# EOS-S3 register map
File version: 0.1
CPU: CM4 r0p1, selectable endian, MPU, FPU, 3 interrupt priority bits
Registers are 32-bit, read-write, reset 0x0 unless marked. A register's access mark holds for its fields unless they carry their own. Offsets are from the block's base; [hi:lo] are bit positions; {n}, {i} and the like mark numbered series.

## MISC — MISC registers
Base 0x40005000
0x00 DBG_MON ro — Debug Monitor information
  [7:0] DEBUG_MON — Reads the debug status/information
0x04 SUBSYS_DBG_MON_SEL — Register for selecting the subsystem routed to the debug monitor
  [2:0] SUBSYS_DEBUG_MON_SEL — Select which subsystem the debug monitors are routed from
    0=Monitor A0 subsystem; 1=monitor_cpu (Monitor the CPU subsystem); 3=monitor_ffe (Monitor the FPGA Fabric subsystem); 4=monitor_audio (Monitor the audio subsystem)
0x08 A0_DBG_MON_SEL — Select A0 debug monitors
  [2:0] A0_DEBUG_MON_SEL — Select debug monitors
    0=use_pmu_monitor (Selects the PMU monitor as the monitor for the A0 subsystem); 1=use_cru_monitor (Selects the CRU monitor as the monitor for the A0 subsystem)
0x0C A0_PMU_DBG_MON_SEL — Selects the data present in the PMU debug monitor. The output will be (Except 0 and 10), {Status0, Status1, ISO, RET, GateCLK_N, Mem_DS, MP_Gate, RP_Gate)
  [5:0] A0_PMU_DEBUG_MON_SEL — Select data to be shown in the PMU debug monitor
    0=show_m4stm_kickoff_and_busy_plus_0x000000 ({M4STM_KickOff, M4STM_BUSY, 6'h0}); 1=show_a1; 2=show_m4; 3=show_m4s0; 4=show_ad5; 5=show_ad4; 6=show_ad3; 7=show_ad2; 8=show_ad1; 9=show_ad0; 10=show_fbst_kickoff_and_busy_plus_0x000000 ({FBSTM_KickOff, FBSTM_BUSY,6'h0}); 11=show_i2s; 13=show_m4s15; 14=show_m4s11; 15=show_m4s7; 16=show_m4s3; 17=show_pf; 18=show_sdma; 19=show_ffe; 20=show_fb
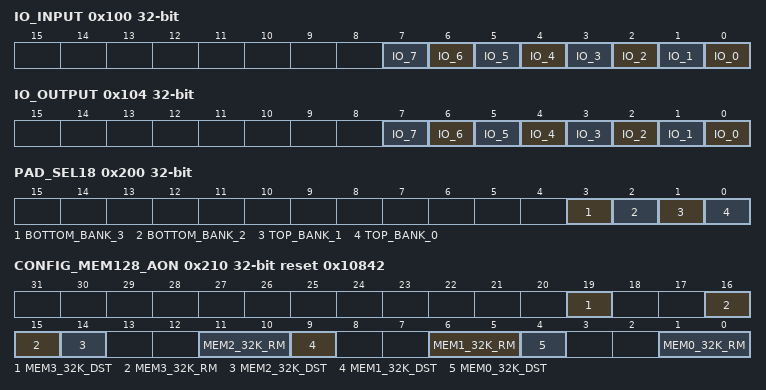
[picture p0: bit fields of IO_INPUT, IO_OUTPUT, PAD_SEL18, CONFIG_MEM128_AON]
0x100 IO_INPUT ro — Reads the value of the IO pins
  [n] IO_{n} (n=0..7) — Read digital value of pin mapped to IO bit {n}
0x104 IO_OUTPUT — Allows FW to drive the IO with the values specified in this register
  [n] IO_{n} (n=0..7) — Write digital value of pin mapped to IO bit {n}
0x110 SW_MB_1 — Software Mailbox (can be used for communication between M4 and AP)
0x114 SW_MB_2 — Software Mailbox (can be used for communication between M4 and AP)
0x200 PAD_SEL18 — Select 1.8V for VCCIO for up to 4 banks. Write a 1 to a bank field to make the IO VCC = 1.8V
  [3] BOTTOM_BANK_3 — bit for bottom bank 1
  [2] BOTTOM_BANK_2 — bit for bottom bank 0
  [1] TOP_BANK_1 — bit for top bank 1
  [0] TOP_BANK_0 — bit for top bank 0
0x210 CONFIG_MEM128_AON reset 0x10842 — Memory Configuration
  [19] MEM3_32K_DST ro — Disable-Self-Time. When asserted high, overrides the self-timed circuitry and causes the read margin to be controlled by the falling clk edge. Requires margin[] to be set to 2'b00. This pin is intended for debug/FA purposes only.
  [5n+1:5n] MEM{n}_32K_RM (n=0..3) — Read and write margin control. Recommended setting is 2'b10. 2'b00 provides the most margin (slowest speed). 2'b11 provides the least margin (fastest speed) memory. This setting is required for VDDMIN operation.
  [14] MEM2_32K_DST — Disable-Self-Time. When asserted high, overrides the self-timed circuitry and causes the read margin to be controlled by the falling clk edge. Requires margin[] to be set to 2'b00. This pin is intended for debug/FA purposes only.
  [9] MEM1_32K_DST — Disable-Self-Time. When asserted high, overrides the self-timed circuitry and causes the read margin to be controlled by the falling clk edge. Requires margin[] to be set to 2'b00. This pin is intended for debug/FA purposes only.
  [4] MEM0_32K_DST — Disable-Self-Time. When asserted high, overrides the self-timed circuitry and causes the read margin to be controlled by the falling clk edge. Requires margin[] to be set to 2'b00. This pin is intended for debug/FA purposes only.
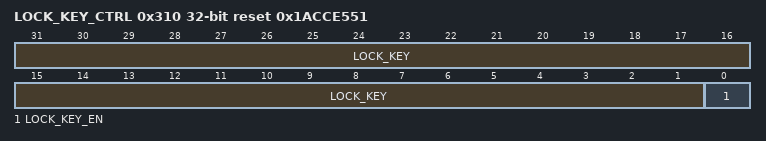
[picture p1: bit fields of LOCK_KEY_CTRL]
0x310 LOCK_KEY_CTRL reset 0x1ACCE551 — Control value and status of LOCK_KEY
  [31:1] LOCK_KEY wo — Enable write access to all below registers by writing 0x1ACCE551. Disable write access by writing any other value. M4 WDT Intr/reset clear - 0x4000_4830[4:3], M4 WDT Intr/reset enable AP - 0x4000_4834[4:3], Pad #43 (AP_INTR) - 0x40004CAC[12:0], M4 Low Power Configuration - 0x40004484[1:0], M4 WDT Clock Gate - 0x40004054[0]
  [0] LOCK_KEY_EN — 0: lock disabled, write to register enabled, 1: lock enable, write to register disabled
    0=lock_disable (Disable lock to allow writing the lock_key field); 1=lock_enable (Enable lock to prevent writing the lock_key field)
0x3FC FB_DEVICE_ID ro — Fabric device ID
  [15:0] ID
